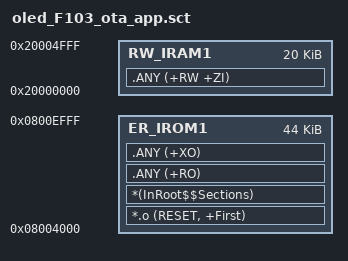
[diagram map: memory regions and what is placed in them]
LR_IROM1 0x08004000 0x0000B000  {
  ER_IROM1 0x08004000 0x0000B000  {
   *.o (RESET, +First)
   *(InRoot$$Sections)
   .ANY (+RO)
   .ANY (+XO)
  }
  RW_IRAM1 0x20000000 0x00005000  {
   .ANY (+RW +ZI)
  }
}
